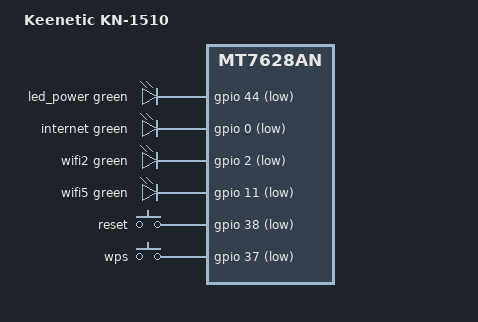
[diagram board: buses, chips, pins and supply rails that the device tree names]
// SPDX-License-Identifier: GPL-2.0-or-later OR MIT

#include "mt7628an_keenetic_kn-1510.dtsi"

/ {
	compatible = "keenetic,kn-1510", "mediatek,mt7628an-soc";
	model = "Keenetic KN-1510";

	leds {
		compatible = "gpio-leds";

		led_power: power {
			function = LED_FUNCTION_POWER;
			color = <LED_COLOR_ID_GREEN>;
			gpios = <&gpio 44 GPIO_ACTIVE_LOW>;
		};

		internet {
			function = LED_FUNCTION_WAN;
			color = <LED_COLOR_ID_GREEN>;
			gpios = <&gpio 0 GPIO_ACTIVE_LOW>;
		};

		wifi2 {
			function = LED_FUNCTION_WLAN_2GHZ;
			color = <LED_COLOR_ID_GREEN>;
			gpios = <&gpio 2 GPIO_ACTIVE_LOW>;
			linux,default-trigger = "phy0tpt";
		};

		wifi5 {
			function = LED_FUNCTION_WLAN_5GHZ;
			color = <LED_COLOR_ID_GREEN>;
			gpios = <&gpio 11 GPIO_ACTIVE_LOW>;
			linux,default-trigger = "phy1tpt";
		};
	};

	keys {
		compatible = "gpio-keys";

		reset {
			label = "reset";
			gpios = <&gpio 38 GPIO_ACTIVE_LOW>;
			linux,code = <KEY_RESTART>;
		};

		wps {
			label = "wps";
			gpios = <&gpio 37 GPIO_ACTIVE_LOW>;
			linux,code = <KEY_WPS_BUTTON>;
		};
	};
};
